# ATA664251 device description
Architecture: AVR8; Family: tinyAVR
Registers are 8-bit, access not given, no defined reset value unless marked. A register's access mark holds for its fields unless they carry their own. Offsets are from the block's base; [hi:lo] are bit positions.

## USI
Instances: USI 0x00
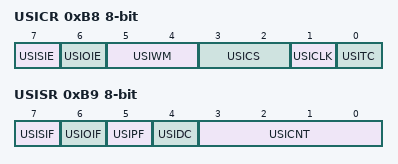
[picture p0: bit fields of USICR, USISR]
0xB8 USICR — USI Control Register
  [7] USISIE — Start Condition Interrupt Enable
  [6] USIOIE — Counter Overflow Interrupt Enable
  [5:4] USIWM — USI Wire Mode Bits
    0=Normal Operation; 1=Three-Wire Mode; 2=Two-Wire Mode; 3=Two-Wire Mode Held Low
  [3:2] USICS — USI Clock Source Select Bits
  [1] USICLK — Clock Strobe
  [0] USITC — Toggle Clock Port Pin
0xB9 USISR — USI Status Register
  [7] USISIF — Start Condition Interrupt Flag
  [6] USIOIF — Counter Overflow Interrupt Flag
  [5] USIPF — Stop Condition Flag
  [4] USIDC — Data Output Collision
  [3:0] USICNT — USI Counter Value Bits
0xBA USIDR — USI Data Register
  [7:0] USIDR — USI Data Register bits
0xBB USIBR — USI Buffer Register
  [7:0] USIBR — USI Buffer Register bits
0xBC USIPP — USI Pin Position
  [0] USIPOS

## TIMER_COUNTER_0
Instances: TIMER_COUNTER_0 0x00
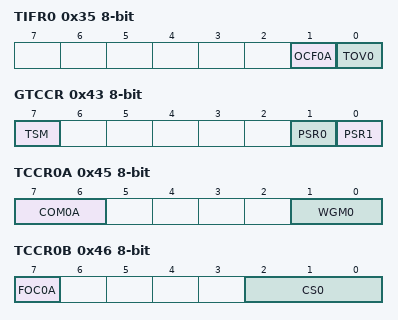
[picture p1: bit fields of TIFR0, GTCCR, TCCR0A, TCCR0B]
0x35 TIFR0 — Timer/Counter0 Interrupt Flag Register
  [1] OCF0A — Output Compare Flag 0A
  [0] TOV0 — Timer/Counter0 Overflow Flag
0x43 GTCCR — General Timer Counter Control register
  [7] TSM — Timer/Counter Synchronization Mode
  [1] PSR0 — Prescaler Reset Asynchronous 8-bit Timer/Counter0
  [0] PSR1 — Prescaler Reset Synchronous 16-bit Timer/Counter1
0x45 TCCR0A — Timer/Counter0 Control Register A
  [7:6] COM0A — Compare Output Mode bits
  [1:0] WGM0 — Waveform Genration Mode bits
0x46 TCCR0B — Timer/Counter0 Control Register B
  [7] FOC0A — Force Output Compare A
  [2:0] CS0 — Clock Select bits
    0=No Clock Source (Stopped); 1=Running, No Prescaling; 2=Running, CLK/8; 3=Running, CLK/32; 4=Running, CLK/64; 5=Running, CLK/128; 6=Running, CLK/256; 7=Running, CLK/1024
0x47 TCNT0 — Timer/Counter0
  [7:0] TCNT0 — Timer/Counter0 bits
0x48 OCR0A — Timer/Counter0 Output Compare Register A
  [7:0] OCR0 — Timer/Counter0 Output Compare Register A bits
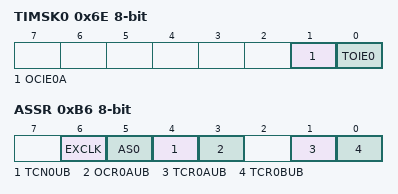
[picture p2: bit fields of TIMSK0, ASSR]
0x6E TIMSK0 — Timer/Counter0 Interrupt Mask register
  [1] OCIE0A — Timer/Counter0 Output Compare Match A Interrupt Enable
  [0] TOIE0 — Timer/Counter0 Overflow Interrupt Enable
0xB6 ASSR — Asynchronous Status Register
  [6] EXCLK — Enable External Clock Input
  [5] AS0 — Asynchronous Timer/Counter0
  [4] TCN0UB — Timer/Counter0 Update Busy
  [3] OCR0AUB — Output Compare Register 0A Update Busy
  [1] TCR0AUB — Timer/Counter0 Control Register A Update Busy
  [0] TCR0BUB — Timer/Counter0 Control Register B Update Busy

## TIMER_COUNTER_1
Instances: TIMER_COUNTER_1 0x00
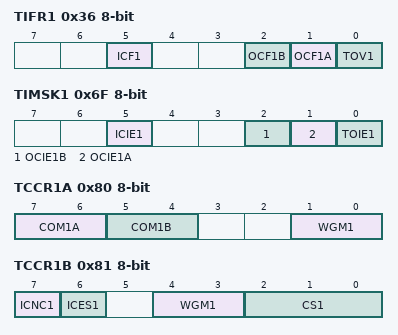
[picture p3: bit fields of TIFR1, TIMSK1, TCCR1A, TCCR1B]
0x36 TIFR1 — Timer/Counter1 Interrupt Flag register
  [5] ICF1 — Timer/Counter1 Input Capture Flag
  [2] OCF1B — Timer/Counter1 Output Compare B Match Flag
  [1] OCF1A — Timer/Counter1 Output Compare A Match Flag
  [0] TOV1 — Timer/Counter1 Overflow Flag
0x6F TIMSK1 — Timer/Counter1 Interrupt Mask Register
  [5] ICIE1 — Timer/Counter1 Input Capture Interrupt Enable
  [2] OCIE1B — Timer/Counter1 Output Compare B Match Interrupt Enable
  [1] OCIE1A — Timer/Counter1 Output Compare A Match Interrupt Enable
  [0] TOIE1 — Timer/Counter1 Overflow Interrupt Enable
0x80 TCCR1A — Timer/Counter1 Control Register A
  [7:6] COM1A — Compare Output Mode 1A, bits
  [5:4] COM1B — Compare Output Mode 1B, bits
  [1:0] WGM1 — Pulse Width Modulator Select Bits
0x81 TCCR1B — Timer/Counter1 Control Register B
  [7] ICNC1 — Input Capture 1 Noise Canceler
  [6] ICES1 — Input Capture 1 Edge Select
  [4:3] WGM1 (bit 2 of the value upward) — Waveform Generation Mode Bits
  [2:0] CS1 — Timer/Counter1 Clock Select bits
    0=No Clock Source (Stopped); 1=Running, No Prescaling; 2=Running, CLK/8; 3=Running, CLK/64; 4=Running, CLK/256; 5=Running, CLK/1024; 6=Running, ExtClk Tx Falling Edge; 7=Running, ExtClk Tx Rising Edge
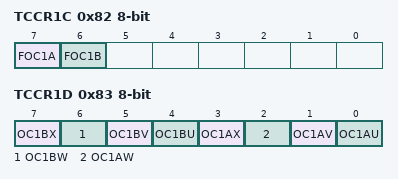
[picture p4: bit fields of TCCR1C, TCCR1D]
0x82 TCCR1C — Timer/Counter1 Control Register C
  [7] FOC1A — Timer/Counter1 Force Output Compare for Channel A
  [6] FOC1B — Timer/Counter1 Force Output Compare for Channel B
0x83 TCCR1D — Timer/Counter1 Control Register D
  [7] OC1BX — Timer/Counter1 Output Compare X-pin Enable for Channel B
  [6] OC1BW — Timer/Counter1 Output Compare W-pin Enable for Channel B
  [5] OC1BV — Timer/Counter1 Output Compare V-pin Enable for Channel B
  [4] OC1BU — Timer/Counter1 Output Compare U-pin Enable for Channel B
  [3] OC1AX — Timer/Counter1 Output Compare X-pin Enable for Channel A
  [2] OC1AW — Timer/Counter1 Output Compare W-pin Enable for Channel A
  [1] OC1AV — Timer/Counter1 Output Compare V-pin Enable for Channel A
  [0] OC1AU — Timer/Counter1 Output Compare U-pin Enable for Channel A
0x84 TCNT1 16-bit — Timer/Counter1 Bytes
0x86 ICR1 16-bit — Timer/Counter1 Input Capture Register Bytes
0x88 OCR1A 16-bit — Timer/Counter1 Output Compare Register A Bytes
0x8A OCR1B 16-bit — Timer/Counter1 Output Compare Register B Bytes
